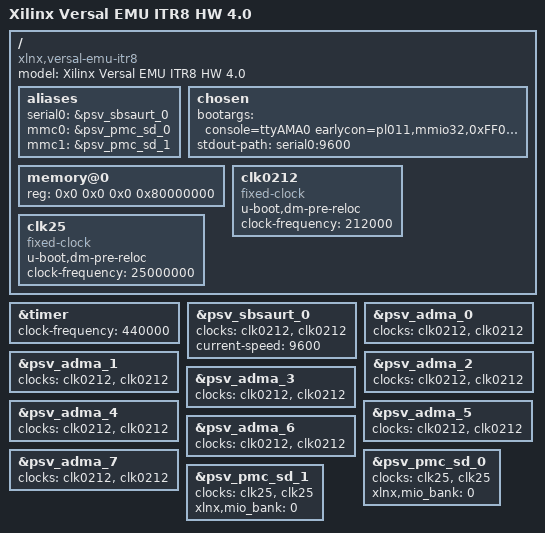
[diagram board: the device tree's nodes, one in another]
/ {
	compatible = "xlnx,versal-emu-itr8", "xlnx,versal-emu", "xlnx,versal";
	#address-cells = <2>;
	#size-cells = <2>;
	model = "Xilinx Versal EMU ITR8 HW 4.0";

	aliases {
		serial0 = &psv_sbsaurt_0;
		mmc0 = &psv_pmc_sd_0;
		mmc1 = &psv_pmc_sd_1;
	};

	chosen {
		bootargs = "console=ttyAMA0 earlycon=pl011,mmio32,0xFF000000,9600n8 clk_ignore_unused maxcpus=1";
		stdout-path = "serial0:9600";
	};

	memory@0 {
		device_type = "memory";
		reg = <0x0 0x0 0x0 0x80000000>;
	};

	clk0212: clk0212 {
		u-boot,dm-pre-reloc;
		compatible = "fixed-clock";
		#clock-cells = <0x0>;
		clock-frequency = <212000>;
	};

	clk25: clk25 {
		u-boot,dm-pre-reloc;
		compatible = "fixed-clock";
		#clock-cells = <0x0>;
		clock-frequency = <25000000>;
	};
};

&timer {
        clock-frequency = <440000>;
};

&psv_sbsaurt_0 {
        status = "okay";
        clocks = <&clk0212 &clk0212>;
	current-speed = <9600>;
};

&psv_adma_0 {
	status = "okay";
	clocks = <&clk0212 &clk0212>;
};

&psv_adma_1 {
	status = "okay";
	clocks = <&clk0212 &clk0212>;
};

&psv_adma_2 {
	status = "okay";
	clocks = <&clk0212 &clk0212>;
};

&psv_adma_3 {
	status = "okay";
	clocks = <&clk0212 &clk0212>;
};

&psv_adma_4 {
	status = "okay";
	clocks = <&clk0212 &clk0212>;
};

&psv_adma_5 {
	status = "okay";
	clocks = <&clk0212 &clk0212>;
};

&psv_adma_6 {
	status = "okay";
	clocks = <&clk0212 &clk0212>;
};

&psv_adma_7 {
	status = "okay";
	clocks = <&clk0212 &clk0212>;
};

&psv_pmc_sd_0 {
	status = "okay";
	clocks = <&clk25 &clk25>;
	xlnx,mio_bank = <0>;
};

&psv_pmc_sd_1 {
	status = "okay";
	clocks = <&clk25 &clk25>;
	xlnx,mio_bank = <0>;
};
